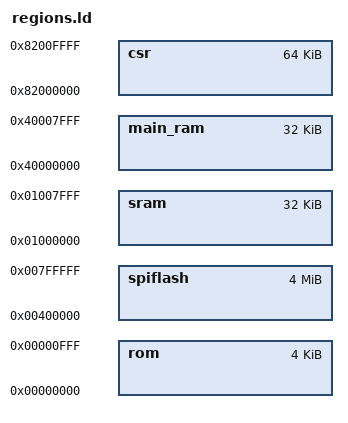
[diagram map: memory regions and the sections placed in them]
MEMORY {
	rom : ORIGIN = 0x00000000, LENGTH = 0x00001000
	sram : ORIGIN = 0x01000000, LENGTH = 0x00008000
	main_ram : ORIGIN = 0x40000000, LENGTH = 0x00008000
	spiflash : ORIGIN = 0x00400000, LENGTH = 0x00400000
	csr : ORIGIN = 0x82000000, LENGTH = 0x00010000
}
